# max32650 register map
Vendor: Maxim-Integrated; Series: ARMCM4; File version: 1.0
CPU: CM4 r2p1, little endian, MPU, FPU, 3 interrupt priority bits
Registers are 32-bit, read-write, reset 0x0 unless marked. A register's access mark holds for its fields unless they carry their own. Offsets are from the block's base; [hi:lo] are bit positions; {n}, {i} and the like mark numbered series.

## SEMA — The Semaphore peripheral allows multiple cores in a system to cooperate when accessing shred resources. The peripheral contains eight semaphores that can be atomically set and cleared. It is left to the discretion of the software architect to decide how and when the semaphores are used and how they are allocated. Existing hardware does not have to be modified for this type of cooperative sharing, and the use of semaphores is exclusively within the software domain.
Base 0x4003E000
{0x0+4i} SEMAPHORES[{i}] (i=0..7) — Read to test and set, returns prior value. Write 0 to clear semaphore.
  [0] sema
0x100 status — Semaphore status bits. 0 indicates the semaphore is free, 1 indicates taken.
  [7:0] STATUS

## SPIXFC_FIFO — SPI XiP Master Controller FIFO.
Base 0x400BC000
0x00 TX_8 8-bit — SPI TX FIFO 8-Bit Write
0x00 TX_16 16-bit (alternate view of TX_8) — SPI TX FIFO 16-Bit Write
0x00 TX_32 (alternate view of TX_8) — SPI TX FIFO 32-Bit Write
0x04 RX_8 8-bit — SPI RX FIFO 8-Bit Access
0x04 RX_16 16-bit (alternate view of RX_8) — SPI RX FIFO 16-Bit Access
0x04 RX_32 (alternate view of RX_8) — SPI RX FIFO 32-Bit Access

## BBFC — Battery Backed Function Control Register.
Base 0x40058000
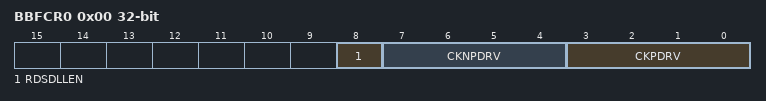
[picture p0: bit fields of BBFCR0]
0x00 BBFCR0 — Register 0.
  [8] RDSDLLEN — Hyperbus RDS DLL Enable.
    0=dis; 1=en
  [7:4] CKNPDRV — Hyperbus CKN Drive Setting.
  [3:0] CKPDRV — Hyperbus CK Drive Setting.

## NBBFC — Non Battery-Backed Function Control Register.
Base 0x40000800
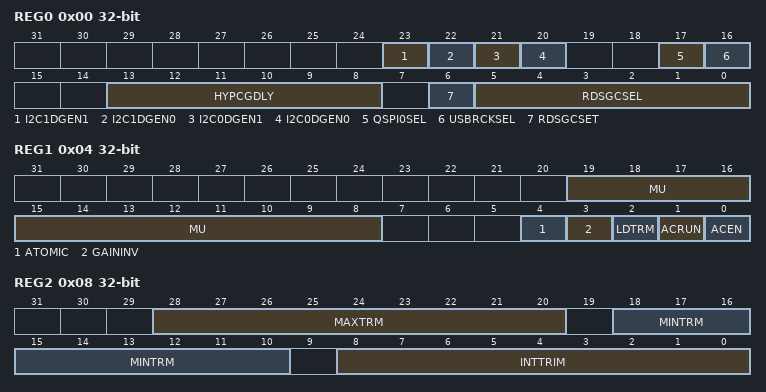
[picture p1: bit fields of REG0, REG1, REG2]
0x00 REG0 — Register 0.
  [23] I2C1DGEN1 — I2C1 SCL Glitch Filter Enable.
    0=dis (Filter disabled.); 1=en (Filter enabled.)
  [22] I2C1DGEN0 — I2C1 SDA Glitch Filter Enable.
    0=dis (Filter disabled.); 1=en (Filter enabled.)
  [21] I2C0DGEN1 — I2C0 SCL Glitch Filter Enable.
    0=dis (Filter disabled.); 1=en (Filter enabled.)
  [20] I2C0DGEN0 — I2C0 SDA Glitch Filter Enable.
    0=dis (Filter disabled.); 1=en (Filter enabled.)
  [17] QSPI0SEL — QSPI0 Function Select.
    0=med (Select SPI Medical functions.); 1=qspi0 (Select QSPI0 function.)
  [16] USBRCKSEL — USB Reference Clock Select.
    0=sys (Generated clock from system clock.); 1=dig (Digital clock from a GPIO.)
  [13:8] HYPCGDLY — Hyperbus Clock Generator Delay.
  [6] RDSGCSET — Hyperbus RDS Set.
    0=internal (Select internal setting.); 1=gray_code (Select gray code.)
  [5:0] RDSGCSEL — Hyperbus RDS Gray Code Select.
0x04 REG1 — Register 1.
  [19:8] MU — MU value.
  [4] ATOMIC — Atomic mode.
    0=not (Not Running.); 1=run (Running.)
  [3] GAININV — Invert Gain.
    0=not (Not Running.); 1=run (Running.)
  [2] LDTRM — Load Trim.
  [1] ACRUN — Autocalibration Run.
    0=not (Not Running.); 1=run (Running.)
  [0] ACEN — Auto-calibration Enable.
    0=dis (Disabled.); 1=en (Enabled.)
0x08 REG2 — Register 2.
  [28:20] MAXTRM — Maximum Trim Setting.
  [18:10] MINTRM — Minimum Trim Setting.
  [8:0] INTTRIM — Initial Trim Setting.
0x0C REG3 — Register 3.
  [7:0] DONECNT — Automatic Calibration Done Counter Setting.

## SIR — System Initialization Registers.
Base 0x40000400
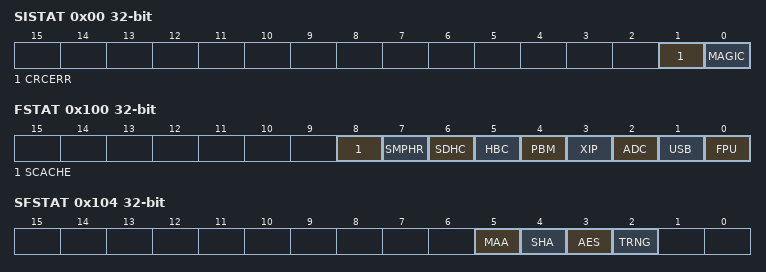
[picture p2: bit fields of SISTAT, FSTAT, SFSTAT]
0x00 SISTAT ro — System Initialization Status Register.
  [1] CRCERR — CRC Error Status. This bit is set by the system initialization block following power-up.
    on read: 0=noError (No CRC errors occurred during the read of the OTP memory block.); 1=error (A CRC error occurred while reading the OTP. The address of the failure location in the OTP memory is stored in the ERRADDR register.)
  [0] MAGIC — Magic Word Validation. This bit is set by the system initialization block following power-up.
    on read: 0=magicNotSet (Magic word was not set (OTP has not been initialized properly).); 1=magicSet (Magic word was set (OTP contains valid settings).)
0x04 ERRADDR ro — Read-only field set by the SIB block if a CRC error occurs during the read of the OTP memory. Contains the failing address in OTP memory (when CRCERR equals 1).
0x100 FSTAT ro — funcstat register.
  [all] fields
    0=no; 1=yes
  [8] SCACHE — SRCC function.
  [7] SMPHR — SMPHR function.
  [6] SDHC — SDHC function.
  [5] HBC — Hyperbus Control Function.
  [4] PBM — Pixel Bit Manipulator Function.
  [3] XIP — XiP function.
  [2] ADC — 10-bit Sigma Delta ADC.
  [1] USB — USB Device.
  [0] FPU — FPU Function.
0x104 SFSTAT ro — secfuncstat register.
  [all] fields
    0=no; 1=yes
  [5] MAA — MAA function.
  [4] SHA — SHA function.
  [3] AES — AES function.
  [2] TRNG — TRNG function.
